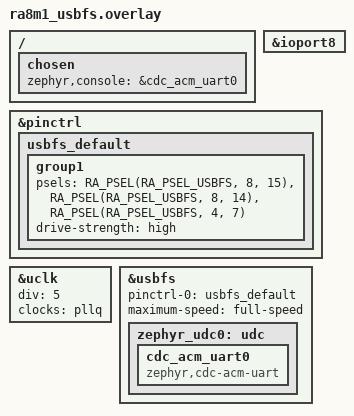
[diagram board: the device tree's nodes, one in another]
/* By default usbhs is enabled with label zephyr_udc0, we need to remove them to enable usbfs */
/delete-node/ &usbhs_phy;
/delete-node/ &usbhs;

/* Port 8 must be enabled to expose the USB FS pins (P8.14, P8.15). */
&ioport8 {
    status = "okay";
};

&pinctrl {
    usbfs_default: usbfs_default {
        group1 {
            /* USB FS differential pair (USBP = P8.15, USBN = P8.14) */
            /* and VBUS sense (P4.7).                                 */
            psels = <RA_PSEL(RA_PSEL_USBFS, 8, 15)>,
                    <RA_PSEL(RA_PSEL_USBFS, 8, 14)>,
                    <RA_PSEL(RA_PSEL_USBFS, 4, 7)>;
            drive-strength = "high";
        };
    };
};

/* UCLK (USB clock) must be exactly 48 MHz.                          */
/* PLL output = XTAL (20 MHz) / 1 * 12 = 240 MHz.                    */
/* UCLK = 240 MHz / 5 = 48 MHz ...                                   */
&uclk {
    status = "okay";
    div = <5>;
    clocks = <&pllq>;
};

/* USB FS peripheral. Runs at full-speed (12 Mbit/s).                */
/* Exposes a single CDC ACM UART device used as the serial console   */
/* and data interface.                                               */
&usbfs {
    status = "okay";
    pinctrl-0 = <&usbfs_default>;
    pinctrl-names = "default";
    maximum-speed = "full-speed";
    zephyr_udc0: udc {
        status = "okay";
        cdc_acm_uart0: cdc_acm_uart0 {
            compatible = "zephyr,cdc-acm-uart";
        };
    };
};
/ {
    chosen {
        zephyr,console = &cdc_acm_uart0;
    };
};
